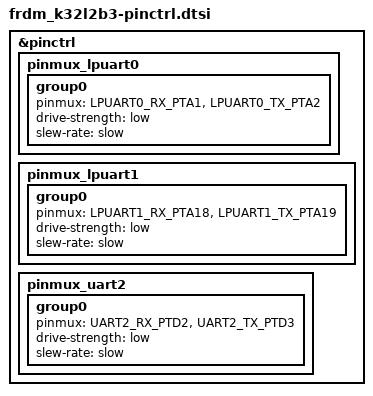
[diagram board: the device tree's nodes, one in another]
/*
 * SPDX-License-Identifier: Apache-2.0
 */

#include <nxp/kinetis/K32L2B31VLH0A-pinctrl.h>

&pinctrl {
	pinmux_lpuart0: pinmux_lpuart0 {
		group0 {
			pinmux =
				<LPUART0_RX_PTA1>,
				<LPUART0_TX_PTA2>;
			drive-strength = "low";
			slew-rate = "slow";
		};
	};
	pinmux_lpuart1: pinmux_lpuart1 {
		group0 {
			pinmux =
				<LPUART1_RX_PTA18>,
				<LPUART1_TX_PTA19>;
			drive-strength = "low";
			slew-rate = "slow";
		};
	};
	pinmux_uart2: pinmux_uart2 {
		group0 {
			pinmux =
				<UART2_RX_PTD2>,
				<UART2_TX_PTD3>;
			drive-strength = "low";
			slew-rate = "slow";
		};
	};
};
